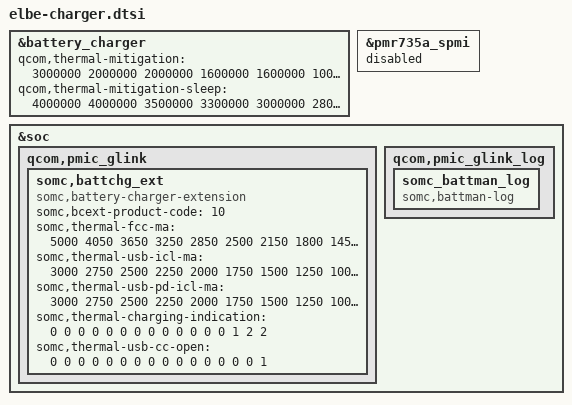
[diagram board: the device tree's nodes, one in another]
&battery_charger {
	qcom,thermal-mitigation = <3000000 2000000 2000000 1600000 1600000 1000000 1000000
				1000000 400000 400000 100000 100000 0 2000000
				1000000 600000 400000 200000 100000 100000 0 0>;
	qcom,thermal-mitigation-sleep = <4000000 4000000 3500000 3300000 3000000 2800000 2400000
				2200000 1600000 400000 100000 100000 0 2000000
				1000000 600000 400000 200000 100000 100000 0 0>;
};

&pmr735a_spmi {
	status = "disabled";
};

&soc {
	qcom,pmic_glink {
		somc,battchg_ext {
			compatible = "somc,battery-charger-extension";

			somc,bcext-product-code = <10>;
			somc,thermal-fcc-ma = <5000 4050 3650 3250 2850 2500 2150
						1800 1450 1100 750 400 50 0 0 0>;
			somc,thermal-usb-icl-ma = <3000 2750 2500 2250 2000 1750 1500
						1250 1000 750 500 250 100 0 0 0>;
			somc,thermal-usb-pd-icl-ma = <3000 2750 2500 2250 2000 1750 1500
						1250 1000 750 500 250 100 0 0 0>;
			somc,thermal-charging-indication = <0 0 0 0 0 0 0 0 0 0 0 0 0 1 2 2>;
			somc,thermal-usb-cc-open = <0 0 0 0 0 0 0 0 0 0 0 0 0 0 0 1>;
		};
	};

	qcom,pmic_glink_log {
		status = "okay";

		somc_battman_log {
			compatible = "somc,battman-log";
		};
	};
};
